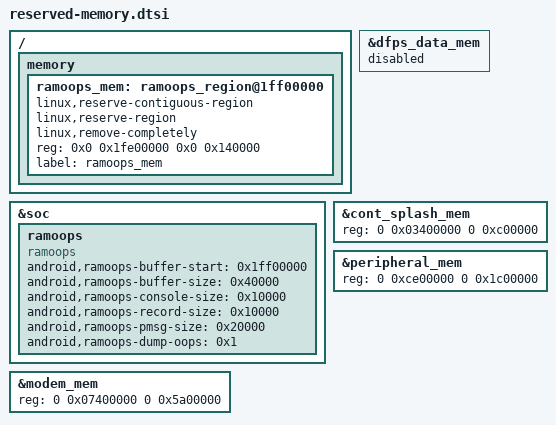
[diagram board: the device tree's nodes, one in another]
/ {
	memory {
		#address-cells = <2>;
		#size-cells = <2>;

		ramoops_mem: ramoops_region@1ff00000 {
			linux,reserve-contiguous-region;
			linux,reserve-region;
			linux,remove-completely;
			/* Hardboot: reserve 1MB of space
			 * before ramoops address of 0x1ff00000
			 */
			reg = <0x0 0x1fe00000 0x0 0x140000>;
			label = "ramoops_mem";
		};
	};
};

&soc {
	ramoops {
		compatible = "ramoops";
		status = "okay";

		android,ramoops-buffer-start = <0x1ff00000>;
		android,ramoops-buffer-size =  <0x40000>;
		android,ramoops-console-size = <0x10000>;
		android,ramoops-record-size = <0x10000>;
		android,ramoops-pmsg-size = <0x20000>;
		android,ramoops-dump-oops = <0x1>;
	};
};

&dfps_data_mem {
	status = "disabled";
};

&cont_splash_mem {
	reg = <0 0x03400000 0 0xc00000>;
};

&peripheral_mem {
	reg = <0 0xce00000 0 0x1c00000>;
};

&modem_mem {
	reg = <0 0x07400000 0 0x5a00000>;
};



